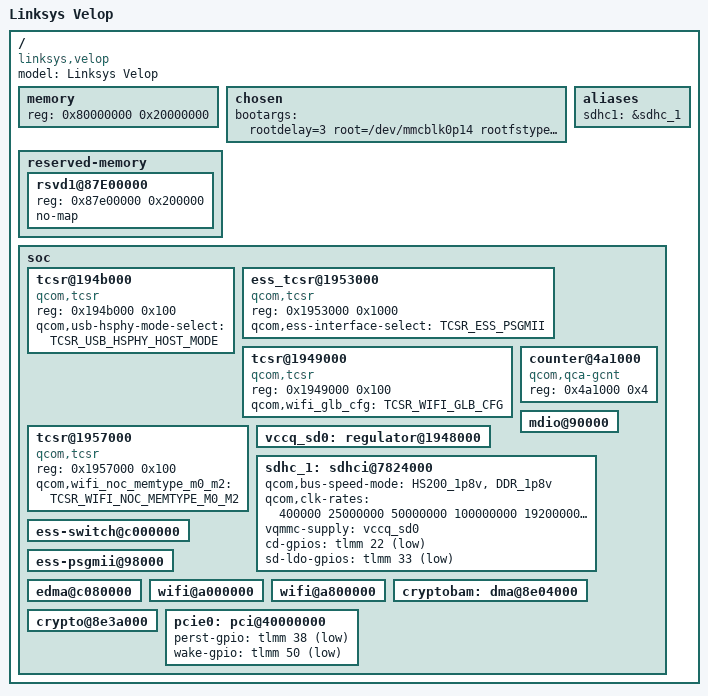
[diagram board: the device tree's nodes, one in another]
/* Copyright (c) 2015, The Linux Foundation. All rights reserved.
 *
 * Permission to use, copy, modify, and/or distribute this software for any
 * purpose with or without fee is hereby granted, provided that the above
 * copyright notice and this permission notice appear in all copies.
 *
 * THE SOFTWARE IS PROVIDED "AS IS" AND THE AUTHOR DISCLAIMS ALL WARRANTIES
 * WITH REGARD TO THIS SOFTWARE INCLUDING ALL IMPLIED WARRANTIES OF
 * MERCHANTABILITY AND FITNESS. IN NO EVENT SHALL THE AUTHOR BE LIABLE FOR
 * ANY SPECIAL, DIRECT, INDIRECT, OR CONSEQUENTIAL DAMAGES OR ANY DAMAGES
 * WHATSOEVER RESULTING FROM LOSS OF USE, DATA OR PROFITS, WHETHER IN AN
 * ACTION OF CONTRACT, NEGLIGENCE OR OTHER TORTIOUS ACTION, ARISING OUT OF
 * OR IN CONNECTION WITH THE USE OR PERFORMANCE OF THIS SOFTWARE.
 *
 */

#include "qcom-ipq4019-ap.dk01.1.dtsi"
#include "qcom-ipq4019-bus.dtsi"
#include <dt-bindings/gpio/gpio.h>
#include <dt-bindings/input/input.h>
#include <dt-bindings/soc/qcom,tcsr.h>

/ {
	model = "Linksys Velop";
	compatible = "linksys,velop", "qcom,ipq4019";

	memory {
		device_type = "memory";
		reg = <0x80000000 0x20000000>;
	};

	chosen {
		bootargs = "rootdelay=3 root=/dev/mmcblk0p14 rootfstype=squashfs,ext4";
	};

	aliases {
		sdhc1 = &sdhc_1;
	};

	reserved-memory {
		#address-cells = <0x1>;
		#size-cells = <0x1>;
		ranges;

		rsvd1@87E00000 {
			reg = <0x87e00000 0x200000>;
			no-map;
		};
	};

	soc {
		tcsr@194b000 {
			compatible = "qcom,tcsr";
			reg = <0x194b000 0x100>;
			qcom,usb-hsphy-mode-select = <TCSR_USB_HSPHY_HOST_MODE>;
			status = "ok";
		};

		ess_tcsr@1953000 {
			compatible = "qcom,tcsr";
			reg = <0x1953000 0x1000>;
			qcom,ess-interface-select = <TCSR_ESS_PSGMII>;
		};


		tcsr@1949000 {
			compatible = "qcom,tcsr";
			reg = <0x1949000 0x100>;
			qcom,wifi_glb_cfg = <TCSR_WIFI_GLB_CFG>;
		};

		tcsr@1957000 {
			compatible = "qcom,tcsr";
			reg = <0x1957000 0x100>;
			qcom,wifi_noc_memtype_m0_m2 = <TCSR_WIFI_NOC_MEMTYPE_M0_M2>;
		};

		counter@4a1000 {
			compatible = "qcom,qca-gcnt";
			reg = <0x4a1000 0x4>;
		};

		mdio@90000 {
			status = "okay";
		};

		vccq_sd0: regulator@1948000 {
			status = "okay";
		};

		sdhc_1: sdhci@7824000{
			status = "ok";
			qcom,bus-speed-mode = "HS200_1p8v", "DDR_1p8v";
			qcom,clk-rates = <400000 25000000
					  50000000 100000000
					  192000000 384000000>;
			vqmmc-supply = <&vccq_sd0>;
			cd-gpios = <&tlmm 22 0x1>;
			sd-ldo-gpios = <&tlmm 33 0x1>;
		};

		ess-switch@c000000 {
			status = "okay";
		};

		ess-psgmii@98000 {
			status = "okay";
		};

		edma@c080000 {
			status = "okay";
		};

		wifi@a000000 {
			status = "okay";
		};

		wifi@a800000 {
			status = "okay";
		};

		cryptobam: dma@8e04000 {
			status = "okay";
		};

		crypto@8e3a000 {
			status = "okay";
		};

		pcie0: pci@40000000 {
			status = "ok";
			perst-gpio = <&tlmm 38 0x1>;
			wake-gpio = <&tlmm 50 0x1>;
		};
	};
};
